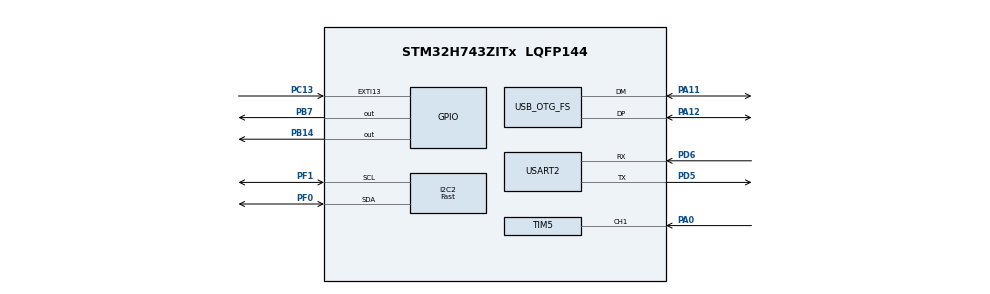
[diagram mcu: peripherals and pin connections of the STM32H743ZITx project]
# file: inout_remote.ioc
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CORTEX_M7.default_mode_Activation=1
Dma.I2C2_TX.0.Direction=DMA_MEMORY_TO_PERIPH
Dma.I2C2_TX.0.EventEnable=DISABLE
Dma.I2C2_TX.0.FIFOMode=DMA_FIFOMODE_DISABLE
Dma.I2C2_TX.0.Instance=DMA1_Stream0
Dma.I2C2_TX.0.MemDataAlignment=DMA_MDATAALIGN_BYTE
Dma.I2C2_TX.0.MemInc=DMA_MINC_ENABLE
Dma.I2C2_TX.0.Mode=DMA_NORMAL
Dma.I2C2_TX.0.PeriphDataAlignment=DMA_PDATAALIGN_BYTE
Dma.I2C2_TX.0.PeriphInc=DMA_PINC_DISABLE
Dma.I2C2_TX.0.Polarity=HAL_DMAMUX_REQ_GEN_RISING
Dma.I2C2_TX.0.Priority=DMA_PRIORITY_HIGH
Dma.I2C2_TX.0.RequestNumber=1
Dma.I2C2_TX.0.SignalID=NONE
Dma.I2C2_TX.0.SyncEnable=DISABLE
Dma.I2C2_TX.0.SyncPolarity=HAL_DMAMUX_SYNC_NO_EVENT
Dma.I2C2_TX.0.SyncRequestNumber=1
Dma.I2C2_TX.0.SyncSignalID=NONE
Dma.Request0=I2C2_TX
I2C2.I2C_Speed_Mode=I2C_Fast
I2C2.Timing=0x00B03FDB
Mcu.Family=STM32H7
Mcu.Name=STM32H743ZITx
Mcu.Package=LQFP144
NUCLEO-H743ZI.BUTTON=1
NUCLEO-H743ZI.Bsp_Common_DEMO=true
NUCLEO-H743ZI.LD1=true
NUCLEO-H743ZI.LD2=true
NUCLEO-H743ZI.LD3=true
NUCLEO-H743ZI.VCP=true
NVIC.DMA1_Stream0_IRQn=true\:0\:0\:false\:false\:true\:false\:true\:true
NVIC.EXTI15_10_IRQn=true\:0\:0\:false\:false\:true\:false\:true\:true
NVIC.OTG_FS_IRQn=true\:0\:0\:false\:false\:true\:false\:true\:true
NVIC.PriorityGroup=NVIC_PRIORITYGROUP_4
NVIC.TIM5_IRQn=true\:0\:0\:false\:false\:true\:true\:true\:true
PA0.Signal=S_TIM5_CH1
PA11.Mode=Device_Only
PA11.Signal=USB_OTG_FS_DM
PA12.Mode=Device_Only
PA12.Signal=USB_OTG_FS_DP
PA13\ (JTMS/SWDIO).GPIO_Label=TMS
PA13\ (JTMS/SWDIO).Signal=DEBUG_JTMS-SWDIO
PA14\ (JTCK/SWCLK).GPIO_Label=TCK
PA14\ (JTCK/SWCLK).Signal=DEBUG_JTCK-SWCLK
PB14.Signal=GPIO_Output
PB3\ (JTDO/TRACESWO).GPIO_Label=SWO
PB3\ (JTDO/TRACESWO).Signal=DEBUG_JTDO-SWO
PB7.Signal=GPIO_Output
PC13.Signal=GPXTI13
PC14-OSC32_IN\ (OSC32_IN).Signal=RCC_OSC32_IN
PC15-OSC32_OUT\ (OSC32_OUT).Signal=RCC_OSC32_OUT
PD5.Mode=Asynchronous
PD5.Signal=USART2_TX
PD6.Mode=Asynchronous
PD6.Signal=USART2_RX
PD8.Signal=USART3_TX
PD9.Signal=USART3_RX
PF0.Mode=I2C
PF0.Signal=I2C2_SDA
PF1.Mode=I2C
PF1.Signal=I2C2_SCL
ProjectManager.HeapSize=0x2000
ProjectManager.StackSize=0x2000
ProjectManager.TargetToolchain=STM32CubeIDE
RCC.48MHZClocksFreq_Value=24000000
RCC.ADCFreq_Value=129000000
RCC.AHBFreq_Value=216000000
RCC.APB1CLKDivider=RCC_HCLK_DIV4
RCC.APB1Freq_Value=120000000
RCC.APB1TimFreq_Value=108000000
RCC.APB2CLKDivider=RCC_HCLK_DIV2
RCC.APB2Freq_Value=120000000
RCC.APB2TimFreq_Value=216000000
RCC.APB3Freq_Value=120000000
RCC.APB4Freq_Value=120000000
RCC.CortexFreq_Value=480000000
RCC.D1PPRE=RCC_APB3_DIV2
RCC.D2PPRE1=RCC_APB1_DIV2
RCC.D2PPRE2=RCC_APB2_DIV2
RCC.D3PPRE=RCC_APB4_DIV2
RCC.DIVM1=4
RCC.DIVN1=60
RCC.DIVQ1=4
RCC.HCLKFreq_Value=240000000
RCC.HPRE=RCC_HCLK_DIV2
RCC.HSE_VALUE=8000000
RCC.HSI_VALUE=64000000
RCC.PLL2FRACN=0
RCC.PLL3FRACN=0
RCC.PLLFRACN=0
RCC.PLLM=25
RCC.PLLMUL=RCC_PLL_MUL9
RCC.PLLN=432
RCC.PLLQ=9
RCC.PRESCALERUSB=RCC_USBCLKSOURCE_PLL_DIV1_5
RCC.PWR_Regulator_Voltage_Scale=PWR_REGULATOR_VOLTAGE_SCALE0
RCC.SYSCLKFreq_VALUE=480000000
RCC.SYSCLKSource=RCC_SYSCLKSOURCE_PLLCLK
RCC.SYSCLKSourceVirtual=RCC_SYSCLKSOURCE_PLLCLK
RCC.USBCLockSelection=RCC_USBCLKSOURCE_HSI48
RCC.USBFreq_Value=48000000
RCC.VCOOutputFreq_Value=432000000
SH.S_TIM5_CH1.0=TIM5_CH1,Input_Capture1_from_TI1
TIM5.AutoReloadPreload=TIM_AUTORELOAD_PRELOAD_DISABLE
TIM5.Channel-Input_Capture1_from_TI1=TIM_CHANNEL_1
TIM5.CounterMode=TIM_COUNTERMODE_UP
TIM5.ICFilter_CH1=10
TIM5.ICPolarity_CH1=TIM_INPUTCHANNELPOLARITY_FALLING
TIM5.Prescaler=239
USART2.VirtualMode-Asynchronous=VM_ASYNC
USB_DEVICE.CLASS_NAME_FS=CDC
USB_DEVICE.VirtualMode-CDC_FS=Cdc
USB_DEVICE.VirtualModeFS=Cdc_FS
USB_OTG_FS.VirtualMode=Device_Only
VP_MEMORYMAP_VS_MEMORYMAP.Mode=CurAppReg
VP_NUCLEO-H743ZI_VS_BSP_COMMON.Mode=COMMON
VP_TIM5_VS_ClockSourceINT.Mode=Internal
VP_USB_DEVICE_VS_USB_DEVICE_CDC_FS.Mode=CDC_FS
board=NUCLEO-H743ZI

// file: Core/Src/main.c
/* USER CODE BEGIN Header */
/**
  ******************************************************************************
  * @file           : main.c
  * @brief          : Main program body
  ******************************************************************************
  * @attention
  *
  * Copyright (c) 2026 STMicroelectronics.
  * All rights reserved.
  *
  * This software is licensed under terms that can be found in the LICENSE file
  * in the root directory of this software component.
  * If no LICENSE file comes with this software, it is provided AS-IS.
  *
  ******************************************************************************
  */
/* USER CODE END Header */
#include "main.h"
#include "dma.h"
#include "i2c.h"
#include "tim.h"
#include "usart.h"
#include "usb_device.h"
#include "gpio.h"

/* USER CODE BEGIN Includes */
#include <stdio.h>
#include "ssd1306.h" // SSD1306 드라이버 헤더 (프로젝트에 있어야 함)
#include "ssd1306_fonts.h"   // 폰트 헤더
#include "usbd_cdc_if.h"
/* USER CODE END Includes */

COM_InitTypeDef BspCOMInit;
__IO uint32_t BspButtonState = BUTTON_RELEASED;

/* USER CODE BEGIN PV */
uint8_t is_work_started = 0;   // 출근 버튼을 누른 적이 있는지 확인하는 플래그
uint32_t lastDisplayUpdate = 0; // 화면 깜빡임 방지용 타이머
/* USER CODE END PV */

void SystemClock_Config(void);
static void MPU_Config(void);
/* USER CODE BEGIN PFP */
void OLED_ShowBitmap_Korean_WorkStart(void);
void OLED_ShowBitmap_Korean_WorkEnd(void);
void OLED_ShowBitmap_Korean_Meeting(void);
void OLED_ShowBitmap_Korean_Trip(void);
void OLED_ShowBitmap_Korean_Away(void);
void OLED_ShowBitmap_Korean_WorkDone(void);
void OLED_ShowUser(int userIndex);
void Display_Countdown(uint32_t remaining_ms);
/* USER CODE END PFP */

/* USER CODE BEGIN 0 */
// 상태 정의
typedef enum {
    STATE_IDLE,
    STATE_WORK_START,   // "출근" 표시 후 5초 대기
    STATE_WORKING,      // 9시간 타이머 작동 중
	STATE_PAUSED,		// 일시정지
    STATE_WORK_DONE,    // "업무시간 종료"
    STATE_MEETING,      // "회의중"
    STATE_TRIP,         // "출장"
    STATE_AWAY          // "부재중"
} SystemState;

SystemState currentState = STATE_IDLE;
int currentUserIndex = 0;
uint32_t stateStartTime = 0;
uint32_t workTimerStart = 0;
const uint32_t WORK_DURATION_MS = 9 * 60 * 60 * 1000; // 9시간

typedef struct {
    SystemState state;          // 현재 상태 (근무중, 회의중 등)
    uint32_t stateStartTime;    // 상태 변경 시각 (5초 문구용)
    uint32_t workTimerStart;    // 업무 시작 시각 (9시간 카운트 기준)
    uint32_t pauseStartTime;    // 일시정지 시작 시각
    uint8_t is_work_started;    // 출근 버튼 눌렀는지 여부 (0 or 1)
} UserData;

UserData users[MAX_USERS];

const unsigned char bitmap_work_start[1024] = {
		0x00, 0x00, 0x00, 0x00, 0x00, 0x00, 0x00, 0x00, 0x00, 0x00, 0x00, 0x00, 0x00, 0x00, 0x00, 0x00,
		0x00, 0x00, 0x00, 0x00, 0x00, 0x00, 0x00, 0x00, 0x00, 0x00, 0x00, 0x00, 0x00, 0x00, 0x00, 0x00,
		0x00, 0x00, 0x00, 0x00, 0x00, 0x00, 0x00, 0x00, 0x00, 0x00, 0x00, 0x00, 0x00, 0x00, 0x00, 0x00,
		0x00, 0x00, 0x00, 0x00, 0x00, 0x00, 0x00, 0x00, 0x00, 0x00, 0x00, 0x00, 0x00, 0x00, 0x00, 0x00,
		0x00, 0x00, 0x00, 0x00, 0x00, 0x00, 0x00, 0x00, 0x00, 0x00, 0x00, 0x00, 0x00, 0x00, 0x00, 0x00,
		0x00, 0x00, 0x00, 0x00, 0x00, 0x00, 0x00, 0x00, 0x00, 0x00, 0x00, 0x00, 0x00, 0x00, 0x00, 0x00,
		0x00, 0x00, 0x00, 0x00, 0x00, 0x00, 0x00, 0x00, 0x00, 0x00, 0x00, 0x00, 0x00, 0x00, 0x00, 0x00,
		0x00, 0x00, 0x00, 0x00, 0x00, 0x00, 0x00, 0x00, 0x00, 0x00, 0x00, 0x00, 0x00, 0x00, 0x00, 0x00,
		0x00, 0x00, 0x00, 0x00, 0x00, 0x00, 0x00, 0x00, 0x00, 0x00, 0x00, 0x00, 0x00, 0x00, 0x00, 0x00,
		0x00, 0x00, 0x00, 0x00, 0x00, 0x00, 0x00, 0x00, 0x00, 0x00, 0x00, 0x00, 0x00, 0x00, 0x00, 0x00,
		0x00, 0x00, 0x00, 0x00, 0x00, 0x00, 0x00, 0x00, 0x00, 0x00, 0x00, 0x00, 0x00, 0x00, 0x00, 0x00,
		0x00, 0x00, 0x00, 0x00, 0x00, 0x00, 0x00, 0x00, 0x00, 0x00, 0x00, 0x00, 0x00, 0x00, 0x00, 0x00,
		0x00, 0x00, 0x00, 0x00, 0x00, 0x00, 0x00, 0x00, 0x00, 0x00, 0x00, 0x00, 0x00, 0x00, 0x00, 0x00,
		0x00, 0x00, 0x00, 0x00, 0x00, 0x00, 0x00, 0x00, 0x00, 0x00, 0x00, 0x00, 0x00, 0x00, 0x00, 0x00,
		0x00, 0x00, 0x00, 0x07, 0x00, 0x00, 0x00, 0x00, 0x00, 0x00, 0x00, 0x00, 0x00, 0x00, 0x00, 0x00,
		0x00, 0x00, 0x00, 0x07, 0x00, 0x00, 0x00, 0x3f, 0xff, 0xff, 0xc0, 0x00, 0x00, 0x00, 0x00, 0x00,
		0x00, 0x00, 0x00, 0x07, 0x00, 0x00, 0x00, 0x3f, 0xff, 0xff, 0xc0, 0x00, 0x00, 0x00, 0x00, 0x00,
		0x00, 0x00, 0x7f, 0xff, 0xff, 0xe0, 0x00, 0x3f, 0xff, 0xff, 0xc0, 0x00, 0x00, 0x00, 0x00, 0x00,
		0x00, 0x00, 0x7f, 0xff, 0xff, 0xe0, 0x00, 0x00, 0x00, 0x01, 0xc0, 0x00, 0x00, 0x00, 0x00, 0x00,
		0x00, 0x00, 0x7f, 0xff, 0xff, 0xe0, 0x00, 0x00, 0x00, 0x01, 0xc0, 0x00, 0x00, 0x00, 0x00, 0x00,
		0x00, 0x00, 0x00, 0x0f, 0x00, 0x00, 0x00, 0x00, 0x00, 0x01, 0xc0, 0x00, 0x00, 0x00, 0x00, 0x00,
		0x00, 0x00, 0x00, 0x1f, 0x80, 0x00, 0x00, 0x00, 0x00, 0x01, 0xc0, 0x00, 0x00, 0x00, 0x00, 0x00,
		0x00, 0x00, 0x00, 0x3f, 0xe0, 0x00, 0x00, 0x00, 0x00, 0x01, 0xc0, 0x00, 0x00, 0x00, 0x00, 0x00,
		0x00, 0x00, 0x00, 0xf8, 0xf8, 0x00, 0x00, 0x00, 0x00, 0x01, 0xc0, 0x00, 0x00, 0x00, 0x00, 0x00,
		0x00, 0x00, 0x0f, 0xe0, 0x7f, 0x80, 0x00, 0x00, 0x00, 0x01, 0xc0, 0x00, 0x00, 0x00, 0x00, 0x00,
		0x00, 0x01, 0xff, 0x80, 0x1f, 0xf8, 0x00, 0x00, 0x00, 0x01, 0xc0, 0x00, 0x00, 0x00, 0x00, 0x00,
		0x00, 0x01, 0xfe, 0x00, 0x03, 0xf8, 0x00, 0x00, 0x00, 0x01, 0xc0, 0x00, 0x00, 0x00, 0x00, 0x00,
		0x00, 0x00, 0xe0, 0x00, 0x00, 0x70, 0x00, 0x00, 0x00, 0x01, 0xc0, 0x00, 0x00, 0x00, 0x00, 0x00,
		0x00, 0x00, 0x00, 0x00, 0x00, 0x00, 0x00, 0x00, 0x00, 0x01, 0xc0, 0x00, 0x00, 0x00, 0x00, 0x00,
		0x00, 0x00, 0x00, 0x00, 0x00, 0x00, 0x00, 0x00, 0x00, 0x01, 0xc0, 0x00, 0x00, 0x00, 0x00, 0x00,
		0x00, 0x07, 0xff, 0xff, 0xff, 0xff, 0x07, 0xff, 0xff, 0xff, 0xff, 0x00, 0x00, 0x00, 0x00, 0x00,
		0x00, 0x07, 0xff, 0xff, 0xff, 0xff, 0x07, 0xff, 0xff, 0xff, 0xff, 0x00, 0x00, 0x00, 0x00, 0x00,
		0x00, 0x07, 0xff, 0xff, 0xff, 0xff, 0x07, 0xff, 0xff, 0xff, 0xff, 0x00, 0x00, 0x00, 0x00, 0x00,
		0x00, 0x00, 0x00, 0x07, 0x00, 0x00, 0x00, 0x00, 0x00, 0x00, 0x00, 0x00, 0x00, 0x00, 0x00, 0x00,
		0x00, 0x00, 0x00, 0x07, 0x00, 0x00, 0x00, 0x00, 0x00, 0x00, 0x00, 0x00, 0x00, 0x00, 0x00, 0x00,
		0x00, 0x00, 0x3f, 0xff, 0xff, 0xc0, 0x00, 0x00, 0x00, 0x00, 0x00, 0x00, 0x00, 0x00, 0x00, 0x00,
		0x00, 0x00, 0x3f, 0xff, 0xff, 0xc0, 0x00, 0x00, 0x00, 0x00, 0x00, 0x00, 0x00, 0x00, 0x00, 0x00,
		0x00, 0x00, 0x3f, 0xff, 0xff, 0xc0, 0x00, 0x1c, 0x00, 0x00, 0x00, 0x00, 0x00, 0x00, 0x00, 0x00,
		0x00, 0x00, 0x00, 0x00, 0x01, 0xc0, 0x00, 0x1c, 0x00, 0x00, 0x00, 0x00, 0x00, 0x00, 0x00, 0x00,
		0x00, 0x00, 0x00, 0x00, 0x01, 0xc0, 0x00, 0x1c, 0x00, 0x00, 0x00, 0x00, 0x00, 0x00, 0x00, 0x00,
		0x00, 0x00, 0x00, 0x00, 0x01, 0xc0, 0x00, 0x1c, 0x00, 0x00, 0x00, 0x00, 0x00, 0x00, 0x00, 0x00,
		0x00, 0x00, 0x3f, 0xff, 0xff, 0xc0, 0x00, 0x1c, 0x00, 0x00, 0x00, 0x00, 0x00, 0x00, 0x00, 0x00,
		0x00, 0x00, 0x3f, 0xff, 0xff, 0xc0, 0x00, 0x1c, 0x00, 0x00, 0x00, 0x00, 0x00, 0x00, 0x00, 0x00,
		0x00, 0x00, 0x3f, 0xff, 0xff, 0xc0, 0x00, 0x1c, 0x00, 0x00, 0x00, 0x00, 0x00, 0x00, 0x00, 0x00,
		0x00, 0x00, 0x38, 0x00, 0x00, 0x00, 0x00, 0x1c, 0x00, 0x00, 0x00, 0x00, 0x00, 0x00, 0x00, 0x00,
		0x00, 0x00, 0x38, 0x00, 0x00, 0x00, 0x00, 0x1c, 0x00, 0x00, 0x00, 0x00, 0x00, 0x00, 0x00, 0x00,
		0x00, 0x00, 0x38, 0x00, 0x00, 0x00, 0x00, 0x1c, 0x00, 0x00, 0x00, 0x00, 0x00, 0x00, 0x00, 0x00,
		0x00, 0x00, 0x3f, 0xff, 0xff, 0xe0, 0x00, 0x1f, 0xff, 0xff, 0xe0, 0x00, 0x00, 0x00, 0x00, 0x00,
		0x00, 0x00, 0x3f, 0xff, 0xff, 0xe0, 0x00, 0x1f, 0xff, 0xff, 0xe0, 0x00, 0x00, 0x00, 0x00, 0x00,
		0x00, 0x00, 0x3f, 0xff, 0xff, 0xe0, 0x00, 0x1f, 0xff, 0xff, 0xe0, 0x00, 0x00, 0x00, 0x00, 0x00,
		0x00, 0x00, 0x00, 0x00, 0x00, 0x00, 0x00, 0x00, 0x00, 0x00, 0x00, 0x00, 0x00, 0x00, 0x00, 0x00,
		0x00, 0x00, 0x00, 0x00, 0x00, 0x00, 0x00, 0x00, 0x00, 0x00, 0x00, 0x00, 0x00, 0x00, 0x00, 0x00,
		0x00, 0x00, 0x00, 0x00, 0x00, 0x00, 0x00, 0x00, 0x00, 0x00, 0x00, 0x00, 0x00, 0x00, 0x00, 0x00,
		0x00, 0x00, 0x00, 0x00, 0x00, 0x00, 0x00, 0x00, 0x00, 0x00, 0x00, 0x00, 0x00, 0x00, 0x00, 0x00,
		0x00, 0x00, 0x00, 0x00, 0x00, 0x00, 0x00, 0x00, 0x00, 0x00, 0x00, 0x00, 0x00, 0x00, 0x00, 0x00,
		0x00, 0x00, 0x00, 0x00, 0x00, 0x00, 0x00, 0x00, 0x00, 0x00, 0x00, 0x00, 0x00, 0x00, 0x00, 0x00,
		0x00, 0x00, 0x00, 0x00, 0x00, 0x00, 0x00, 0x00, 0x00, 0x00, 0x00, 0x00, 0x00, 0x00, 0x00, 0x00,
		0x00, 0x00, 0x00, 0x00, 0x00, 0x00, 0x00, 0x00, 0x00, 0x00, 0x00, 0x00, 0x00, 0x00, 0x00, 0x00,
		0x00, 0x00, 0x00, 0x00, 0x00, 0x00, 0x00, 0x00, 0x00, 0x00, 0x00, 0x00, 0x00, 0x00, 0x00, 0x00,
		0x00, 0x00, 0x00, 0x00, 0x00, 0x00, 0x00, 0x00, 0x00, 0x00, 0x00, 0x00, 0x00, 0x00, 0x00, 0x00,
		0x00, 0x00, 0x00, 0x00, 0x00, 0x00, 0x00, 0x00, 0x00, 0x00, 0x00, 0x00, 0x00, 0x00, 0x00, 0x00,
		0x00, 0x00, 0x00, 0x00, 0x00, 0x00, 0x00, 0x00, 0x00, 0x00, 0x00, 0x00, 0x00, 0x00, 0x00, 0x00,
		0x00, 0x00, 0x00, 0x00, 0x00, 0x00, 0x00, 0x00, 0x00, 0x00, 0x00, 0x00, 0x00, 0x00, 0x00, 0x00,
		0x00, 0x00, 0x00, 0x00, 0x00, 0x00, 0x00, 0x00, 0x00, 0x00, 0x00, 0x00, 0x00, 0x00, 0x00, 0x00
};
const unsigned char bitmap_work_end[1024] = {0x00, 0x00, 0x00, 0x00, 0x00, 0x00, 0x00, 0x00, 0x00, 0x00, 0x00, 0x00, 0x00, 0x00, 0x00, 0x00,
		0x00, 0x00, 0x00, 0x00, 0x00, 0x00, 0x00, 0x00, 0x00, 0x00, 0x00, 0x00, 0x00, 0x00, 0x00, 0x00,
		0x00, 0x00, 0x00, 0x00, 0x00, 0x00, 0x00, 0x00, 0x00, 0x00, 0x00, 0x00, 0x00, 0x00, 0x00, 0x00,
		0x00, 0x00, 0x00, 0x00, 0x00, 0x00, 0x00, 0x00, 0x00, 0x00, 0x00, 0x00, 0x00, 0x00, 0x00, 0x00,
		0x00, 0x00, 0x00, 0x00, 0x00, 0x00, 0x00, 0x00, 0x00, 0x00, 0x00, 0x00, 0x00, 0x00, 0x00, 0x00,
		0x00, 0x00, 0x00, 0x00, 0x00, 0x00, 0x00, 0x00, 0x00, 0x00, 0x00, 0x00, 0x00, 0x00, 0x00, 0x00,
		0x00, 0x00, 0x00, 0x00, 0x00, 0x38, 0x00, 0x00, 0x00, 0x00, 0x00, 0x00, 0x00, 0x00, 0x00, 0x00,
		0x00, 0x00, 0x00, 0x00, 0x00, 0x38, 0x00, 0x1f, 0xff, 0xff, 0xe0, 0x00, 0x00, 0x00, 0x00, 0x00,
		0x00, 0x00, 0x00, 0x00, 0x00, 0x38, 0x00, 0x1f, 0xff, 0xff, 0xe0, 0x00, 0x00, 0x00, 0x00, 0x00,
		0x00, 0x00, 0x00, 0x00, 0x00, 0x38, 0x00, 0x1f, 0xff, 0xff, 0xe0, 0x00, 0x00, 0x00, 0x00, 0x00,
		0x00, 0x00, 0x3f, 0xff, 0xf0, 0x38, 0x00, 0x00, 0x00, 0x00, 0xe0, 0x00, 0x00, 0x00, 0x00, 0x00,
		0x00, 0x00, 0x3f, 0xff, 0xf0, 0x38, 0x00, 0x00, 0x00, 0x00, 0xe0, 0x00, 0x00, 0x00, 0x00, 0x00,
		0x00, 0x00, 0x3f, 0xff, 0xf0, 0x38, 0x00, 0x00, 0x00, 0x00, 0xe0, 0x00, 0x00, 0x00, 0x00, 0x00,
		0x00, 0x00, 0x30, 0x00, 0x00, 0x38, 0x00, 0x00, 0x00, 0x00, 0xe0, 0x00, 0x00, 0x00, 0x00, 0x00,
		0x00, 0x00, 0x30, 0x00, 0x00, 0x38, 0x00, 0x00, 0x00, 0x00, 0xe0, 0x00, 0x00, 0x00, 0x00, 0x00,
		0x00, 0x00, 0x30, 0x00, 0x00, 0x38, 0x00, 0x00, 0x00, 0x00, 0xe0, 0x00, 0x00, 0x00, 0x00, 0x00,
		0x00, 0x00, 0x30, 0x00, 0x00, 0x38, 0x00, 0x00, 0x00, 0x00, 0xe0, 0x00, 0x00, 0x00, 0x00, 0x00,
		0x00, 0x00, 0x3f, 0xff, 0xf0, 0x38, 0x00, 0x00, 0x00, 0x00, 0xe0, 0x00, 0x00, 0x00, 0x00, 0x00,
		0x00, 0x00, 0x3f, 0xff, 0xf0, 0x38, 0x00, 0x00, 0x00, 0x00, 0xe0, 0x00, 0x00, 0x00, 0x00, 0x00,
		0x00, 0x00, 0x3f, 0xff, 0xf0, 0x38, 0x00, 0x00, 0x00, 0x00, 0xe0, 0x00, 0x00, 0x00, 0x00, 0x00,
		0x00, 0x00, 0x30, 0x00, 0x00, 0x38, 0x00, 0x00, 0x00, 0x00, 0xe0, 0x00, 0x00, 0x00, 0x00, 0x00,
		0x00, 0x00, 0x30, 0x00, 0x00, 0x38, 0x00, 0x00, 0x00, 0x00, 0xe0, 0x00, 0x00, 0x00, 0x00, 0x00,
		0x00, 0x00, 0x30, 0x00, 0x00, 0x38, 0x03, 0xff, 0xff, 0xff, 0xff, 0x80, 0x00, 0x00, 0x00, 0x00,
		0x00, 0x00, 0x30, 0x00, 0x00, 0x38, 0x03, 0xff, 0xff, 0xff, 0xff, 0x80, 0x00, 0x00, 0x00, 0x00,
		0x00, 0x00, 0x30, 0x00, 0x00, 0x38, 0x03, 0xff, 0xff, 0xff, 0xff, 0x80, 0x00, 0x00, 0x00, 0x00,
		0x00, 0x00, 0x3f, 0xff, 0xf8, 0x38, 0x00, 0x00, 0x00, 0x00, 0x00, 0x00, 0x00, 0x00, 0x00, 0x00,
		0x00, 0x00, 0x3f, 0xff, 0xf8, 0x38, 0x00, 0x00, 0x00, 0x00, 0x00, 0x00, 0x00, 0x00, 0x00, 0x00,
		0x00, 0x00, 0x3f, 0xff, 0xf8, 0x38, 0x00, 0x00, 0x00, 0x00, 0x00, 0x00, 0x00, 0x00, 0x00, 0x00,
		0x00, 0x00, 0x00, 0x38, 0x00, 0x38, 0x00, 0x00, 0x00, 0x00, 0x00, 0x00, 0x00, 0x00, 0x00, 0x00,
		0x00, 0x00, 0x00, 0x38, 0x00, 0x38, 0x00, 0x0e, 0x00, 0x00, 0x00, 0x00, 0x00, 0x00, 0x00, 0x00,
		0x00, 0x00, 0x00, 0x38, 0x00, 0x38, 0x00, 0x0e, 0x00, 0x00, 0x00, 0x00, 0x00, 0x00, 0x00, 0x00,
		0x00, 0x00, 0x00, 0x38, 0x00, 0x38, 0x00, 0x0e, 0x00, 0x00, 0x00, 0x00, 0x00, 0x00, 0x00, 0x00,
		0x00, 0x00, 0x00, 0x38, 0x00, 0x38, 0x00, 0x0e, 0x00, 0x00, 0x00, 0x00, 0x00, 0x00, 0x00, 0x00,
		0x00, 0x00, 0x00, 0x38, 0x00, 0x38, 0x00, 0x0e, 0x00, 0x00, 0x00, 0x00, 0x00, 0x00, 0x00, 0x00,
		0x00, 0x00, 0x00, 0x38, 0x7f, 0x38, 0x00, 0x0e, 0x00, 0x00, 0x00, 0x00, 0x00, 0x00, 0x00, 0x00,
		0x00, 0x03, 0xff, 0xff, 0xff, 0x38, 0x00, 0x0e, 0x00, 0x00, 0x00, 0x00, 0x00, 0x00, 0x00, 0x00,
		0x00, 0x03, 0xff, 0xff, 0xff, 0x38, 0x00, 0x0e, 0x00, 0x00, 0x00, 0x00, 0x00, 0x00, 0x00, 0x00,
		0x00, 0x03, 0xff, 0xff, 0x80, 0x38, 0x00, 0x0e, 0x00, 0x00, 0x00, 0x00, 0x00, 0x00, 0x00, 0x00,
		0x00, 0x00, 0x00, 0x00, 0x00, 0x38, 0x00, 0x0e, 0x00, 0x00, 0x00, 0x00, 0x00, 0x00, 0x00, 0x00,
		0x00, 0x00, 0x00, 0x00, 0x00, 0x38, 0x00, 0x0f, 0xff, 0xff, 0xf0, 0x00, 0x00, 0x00, 0x00, 0x00,
		0x00, 0x00, 0x00, 0x00, 0x00, 0x38, 0x00, 0x0f, 0xff, 0xff, 0xf0, 0x00, 0x00, 0x00, 0x00, 0x00,
		0x00, 0x00, 0x00, 0x00, 0x00, 0x38, 0x00, 0x0f, 0xff, 0xff, 0xf0, 0x00, 0x00, 0x00, 0x00, 0x00,
		0x00, 0x00, 0x00, 0x00, 0x00, 0x38, 0x00, 0x00, 0x00, 0x00, 0x00, 0x00, 0x00, 0x00, 0x00, 0x00,
		0x00, 0x00, 0x00, 0x00, 0x00, 0x38, 0x00, 0x00, 0x00, 0x00, 0x00, 0x00, 0x00, 0x00, 0x00, 0x00,
		0x00, 0x00, 0x00, 0x00, 0x00, 0x00, 0x00, 0x00, 0x00, 0x00, 0x00, 0x00, 0x00, 0x00, 0x00, 0x00,
		0x00, 0x00, 0x00, 0x00, 0x00, 0x00, 0x00, 0x00, 0x00, 0x00, 0x00, 0x00, 0x00, 0x00, 0x00, 0x00,
		0x00, 0x00, 0x00, 0x00, 0x00, 0x00, 0x00, 0x00, 0x00, 0x00, 0x00, 0x00, 0x00, 0x00, 0x00, 0x00,
		0x00, 0x00, 0x00, 0x00, 0x00, 0x00, 0x00, 0x00, 0x00, 0x00, 0x00, 0x00, 0x00, 0x00, 0x00, 0x00,
		0x00, 0x00, 0x00, 0x00, 0x00, 0x00, 0x00, 0x00, 0x00, 0x00, 0x00, 0x00, 0x00, 0x00, 0x00, 0x00,
		0x00, 0x00, 0x00, 0x00, 0x00, 0x00, 0x00, 0x00, 0x00, 0x00, 0x00, 0x00, 0x00, 0x00, 0x00, 0x00,
		0x00, 0x00, 0x00, 0x00, 0x00, 0x00, 0x00, 0x00, 0x00, 0x00, 0x00, 0x00, 0x00, 0x00, 0x00, 0x00,
		0x00, 0x00, 0x00, 0x00, 0x00, 0x00, 0x00, 0x00, 0x00, 0x00, 0x00, 0x00, 0x00, 0x00, 0x00, 0x00,
		0x00, 0x00, 0x00, 0x00, 0x00, 0x00, 0x00, 0x00, 0x00, 0x00, 0x00, 0x00, 0x00, 0x00, 0x00, 0x00,
		0x00, 0x00, 0x00, 0x00, 0x00, 0x00, 0x00, 0x00, 0x00, 0x00, 0x00, 0x00, 0x00, 0x00, 0x00, 0x00,
		0x00, 0x00, 0x00, 0x00, 0x00, 0x00, 0x00, 0x00, 0x00, 0x00, 0x00, 0x00, 0x00, 0x00, 0x00, 0x00,
		0x00, 0x00, 0x00, 0x00, 0x00, 0x00, 0x00, 0x00, 0x00, 0x00, 0x00, 0x00, 0x00, 0x00, 0x00, 0x00,
		0x00, 0x00, 0x00, 0x00, 0x00, 0x00, 0x00, 0x00, 0x00, 0x00, 0x00, 0x00, 0x00, 0x00, 0x00, 0x00,
		0x00, 0x00, 0x00, 0x00, 0x00, 0x00, 0x00, 0x00, 0x00, 0x00, 0x00, 0x00, 0x00, 0x00, 0x00, 0x00,
		0x00, 0x00, 0x00, 0x00, 0x00, 0x00, 0x00, 0x00, 0x00, 0x00, 0x00, 0x00, 0x00, 0x00, 0x00, 0x00,
		0x00, 0x00, 0x00, 0x00, 0x00, 0x00, 0x00, 0x00, 0x00, 0x00, 0x00, 0x00, 0x00, 0x00, 0x00, 0x00,
		0x00, 0x00, 0x00, 0x00, 0x00, 0x00, 0x00, 0x00, 0x00, 0x00, 0x00, 0x00, 0x00, 0x00, 0x00, 0x00,
		0x00, 0x00, 0x00, 0x00, 0x00, 0x00, 0x00, 0x00, 0x00, 0x00, 0x00, 0x00, 0x00, 0x00, 0x00, 0x00,
		0x00, 0x00, 0x00, 0x00, 0x00, 0x00, 0x00, 0x00, 0x00, 0x00, 0x00, 0x00, 0x00, 0x00, 0x00, 0x00,
		0x00, 0x00, 0x00, 0x00, 0x00, 0x00, 0x00, 0x00, 0x00, 0x00, 0x00, 0x00, 0x00, 0x00, 0x00, 0x00
};   // 퇴근 이미지 데이터
const unsigned char bitmap_meeting[1024] = {0x00, 0x00, 0x00, 0x00, 0x00, 0x00, 0x00, 0x00, 0x00, 0x00, 0x00, 0x00, 0x00, 0x00, 0x00, 0x00,
		0x00, 0x00, 0x00, 0x00, 0x00, 0x00, 0x00, 0x00, 0x00, 0x00, 0x00, 0x00, 0x00, 0x00, 0x00, 0x00,
		0x00, 0x00, 0x00, 0x00, 0x00, 0x00, 0x00, 0x00, 0x00, 0x00, 0x00, 0x00, 0x00, 0x00, 0x00, 0x00,
		0x00, 0x00, 0x00, 0x00, 0x00, 0x00, 0x00, 0x00, 0x00, 0x00, 0x00, 0x00, 0x00, 0x00, 0x00, 0x00,
		0x00, 0x00, 0x03, 0x80, 0x01, 0xc0, 0x00, 0x00, 0x00, 0x01, 0xc0, 0x00, 0x00, 0x00, 0x00, 0x00,
		0x00, 0x00, 0x03, 0x80, 0x01, 0xc0, 0x00, 0x00, 0x00, 0x01, 0xc0, 0x03, 0xff, 0xff, 0xff, 0xc0,
		0x00, 0x00, 0x03, 0x80, 0x01, 0xc0, 0x00, 0x00, 0x00, 0x01, 0xc0, 0x03, 0xff, 0xff, 0xff, 0xc0,
		0x00, 0x00, 0x03, 0x80, 0x01, 0xc0, 0x00, 0x0f, 0xe0, 0x01, 0xc0, 0x03, 0xff, 0xff, 0xff, 0xc0,
		0x00, 0x00, 0x03, 0x80, 0x01, 0xc0, 0x00, 0x3f, 0xf8, 0x01, 0xc0, 0x00, 0x00, 0x3c, 0x00, 0x00,
		0x00, 0x0f, 0xff, 0xff, 0xe1, 0xc0, 0x00, 0xff, 0xfc, 0x01, 0xc0, 0x00, 0x00, 0x7e, 0x00, 0x00,
		0x00, 0x0f, 0xff, 0xff, 0xe1, 0xc0, 0x01, 0xf0, 0x3e, 0x01, 0xc0, 0x00, 0x00, 0xff, 0x00, 0x00,
		0x00, 0x0f, 0xff, 0xff, 0xe1, 0xc0, 0x01, 0xe0, 0x0f, 0x01, 0xc0, 0x00, 0x03, 0xe7, 0xc0, 0x00,
		0x00, 0x00, 0x00, 0x00, 0x01, 0xc0, 0x03, 0xc0, 0x07, 0x81, 0xc0, 0x00, 0x0f, 0xc3, 0xf0, 0x00,
		0x00, 0x00, 0x00, 0x00, 0x01, 0xc0, 0x03, 0x80, 0x03, 0x81, 0xc0, 0x00, 0xff, 0x00, 0xff, 0x00,
		0x00, 0x00, 0x0f, 0xf0, 0x01, 0xc0, 0x03, 0x80, 0x03, 0x81, 0xc0, 0x07, 0xfe, 0x00, 0x3f, 0xf0,
		0x00, 0x00, 0x7f, 0xfc, 0x01, 0xc0, 0x07, 0x00, 0x03, 0x81, 0xc0, 0x07, 0xf0, 0x00, 0x0f, 0xe0,
		0x00, 0x00, 0xff, 0xfe, 0x01, 0xc0, 0x07, 0x00, 0x03, 0x81, 0xc0, 0x03, 0x80, 0x00, 0x01, 0xc0,
		0x00, 0x01, 0xf0, 0x1f, 0x01, 0xc0, 0x03, 0x80, 0x03, 0x81, 0xc0, 0x00, 0x00, 0x00, 0x00, 0x00,
		0x00, 0x01, 0xc0, 0x07, 0x81, 0xc0, 0x03, 0x80, 0x03, 0x81, 0xc0, 0x00, 0x00, 0x00, 0x00, 0x00,
		0x00, 0x03, 0x80, 0x03, 0x81, 0xc0, 0x03, 0xc0, 0x07, 0x81, 0xc0, 0x00, 0x00, 0x00, 0x00, 0x00,
		0x00, 0x03, 0x80, 0x03, 0x81, 0xc0, 0x01, 0xe0, 0x0f, 0x01, 0xc0, 0x1f, 0xff, 0xff, 0xff, 0xfc,
		0x00, 0x03, 0x80, 0x03, 0x81, 0xc0, 0x01, 0xf0, 0x3e, 0x01, 0xc0, 0x1f, 0xff, 0xff, 0xff, 0xfc,
		0x00, 0x03, 0x80, 0x03, 0x81, 0xc0, 0x00, 0xff, 0xfc, 0x01, 0xc0, 0x1f, 0xff, 0xff, 0xff, 0xfc,
		0x00, 0x01, 0xc0, 0x07, 0x81, 0xc0, 0x00, 0x3f, 0xf8, 0x01, 0xc0, 0x00, 0x00, 0x1c, 0x00, 0x00,
		0x00, 0x01, 0xf0, 0x1f, 0x01, 0xc0, 0x00, 0x0f, 0xe0, 0x01, 0xc0, 0x00, 0x00, 0x1c, 0x00, 0x00,
		0x00, 0x00, 0xff, 0xfe, 0x01, 0xc0, 0x00, 0x00, 0x00, 0x01, 0xc0, 0x00, 0x00, 0x1c, 0x00, 0x00,
		0x00, 0x00, 0x7f, 0xfc, 0x01, 0xc0, 0x00, 0x00, 0x00, 0x01, 0xc0, 0x00, 0x00, 0x1c, 0x00, 0x00,
		0x00, 0x00, 0x1f, 0xf0, 0x01, 0xc0, 0x00, 0x00, 0x00, 0x01, 0xc0, 0x00, 0x03, 0xff, 0xc0, 0x00,
		0x00, 0x00, 0x03, 0x80, 0x01, 0xc0, 0x00, 0x00, 0x00, 0x01, 0xc0, 0x00, 0x1f, 0xff, 0xf8, 0x00,
		0x00, 0x00, 0x03, 0x80, 0x01, 0xc0, 0x00, 0x00, 0x00, 0x01, 0xc0, 0x00, 0x3f, 0xff, 0xfc, 0x00,
		0x00, 0x00, 0x03, 0x80, 0x01, 0xc0, 0x00, 0x00, 0x00, 0x01, 0xc0, 0x00, 0x7e, 0x00, 0x3e, 0x00,
		0x00, 0x00, 0x03, 0x80, 0x01, 0xc0, 0x00, 0x00, 0x00, 0x01, 0xc0, 0x00, 0xf0, 0x00, 0x0f, 0x00,
		0x00, 0x00, 0x03, 0x81, 0xf1, 0xc0, 0x00, 0x00, 0x03, 0xf9, 0xc0, 0x00, 0xe0, 0x00, 0x07, 0x00,
		0x00, 0x1f, 0xff, 0xff, 0xf9, 0xc0, 0x1f, 0xff, 0xff, 0xf9, 0xc0, 0x00, 0xe0, 0x00, 0x07, 0x00,
		0x00, 0x1f, 0xff, 0xff, 0xf9, 0xc0, 0x1f, 0xff, 0xff, 0xf9, 0xc0, 0x00, 0xe0, 0x00, 0x07, 0x00,
		0x00, 0x1f, 0xff, 0xfc, 0x01, 0xc0, 0x1f, 0xff, 0xfc, 0x01, 0xc0, 0x00, 0xf0, 0x00, 0x0f, 0x00,
		0x00, 0x00, 0x00, 0x00, 0x01, 0xc0, 0x00, 0x00, 0x00, 0x01, 0xc0, 0x00, 0x7e, 0x00, 0x7e, 0x00,
		0x00, 0x00, 0x00, 0x00, 0x01, 0xc0, 0x00, 0x00, 0x00, 0x01, 0xc0, 0x00, 0x3f, 0xff, 0xfc, 0x00,
		0x00, 0x00, 0x00, 0x00, 0x01, 0xc0, 0x00, 0x00, 0x00, 0x01, 0xc0, 0x00, 0x0f, 0xff, 0xf8, 0x00,
		0x00, 0x00, 0x00, 0x00, 0x01, 0xc0, 0x00, 0x00, 0x00, 0x01, 0xc0, 0x00, 0x01, 0xff, 0xc0, 0x00,
		0x00, 0x00, 0x00, 0x00, 0x01, 0xc0, 0x00, 0x00, 0x00, 0x01, 0xc0, 0x00, 0x00, 0x00, 0x00, 0x00,
		0x00, 0x00, 0x00, 0x00, 0x01, 0xc0, 0x00, 0x00, 0x00, 0x01, 0xc0, 0x00, 0x00, 0x00, 0x00, 0x00,
		0x00, 0x00, 0x00, 0x00, 0x00, 0x00, 0x00, 0x00, 0x00, 0x00, 0x00, 0x00, 0x00, 0x00, 0x00, 0x00,
		0x00, 0x00, 0x00, 0x00, 0x00, 0x00, 0x00, 0x00, 0x00, 0x00, 0x00, 0x00, 0x00, 0x00, 0x00, 0x00,
		0x00, 0x00, 0x00, 0x00, 0x00, 0x00, 0x00, 0x00, 0x00, 0x00, 0x00, 0x00, 0x00, 0x00, 0x00, 0x00,
		0x00, 0x00, 0x00, 0x00, 0x00, 0x00, 0x00, 0x00, 0x00, 0x00, 0x00, 0x00, 0x00, 0x00, 0x00, 0x00,
		0x00, 0x00, 0x00, 0x00, 0x00, 0x00, 0x00, 0x00, 0x00, 0x00, 0x00, 0x00, 0x00, 0x00, 0x00, 0x00,
		0x00, 0x00, 0x00, 0x00, 0x00, 0x00, 0x00, 0x00, 0x00, 0x00, 0x00, 0x00, 0x00, 0x00, 0x00, 0x00,
		0x00, 0x00, 0x00, 0x00, 0x00, 0x00, 0x00, 0x00, 0x00, 0x00, 0x00, 0x00, 0x00, 0x00, 0x00, 0x00,
		0x00, 0x00, 0x00, 0x00, 0x00, 0x00, 0x00, 0x00, 0x00, 0x00, 0x00, 0x00, 0x00, 0x00, 0x00, 0x00,
		0x00, 0x00, 0x00, 0x00, 0x00, 0x00, 0x00, 0x00, 0x00, 0x00, 0x00, 0x00, 0x00, 0x00, 0x00, 0x00,
		0x00, 0x00, 0x00, 0x00, 0x00, 0x00, 0x00, 0x00, 0x00, 0x00, 0x00, 0x00, 0x00, 0x00, 0x00, 0x00,
		0x00, 0x00, 0x00, 0x00, 0x00, 0x00, 0x00, 0x00, 0x00, 0x00, 0x00, 0x00, 0x00, 0x00, 0x00, 0x00,
		0x00, 0x00, 0x00, 0x00, 0x00, 0x00, 0x00, 0x00, 0x00, 0x00, 0x00, 0x00, 0x00, 0x00, 0x00, 0x00,
		0x00, 0x00, 0x00, 0x00, 0x00, 0x00, 0x00, 0x00, 0x00, 0x00, 0x00, 0x00, 0x00, 0x00, 0x00, 0x00,
		0x00, 0x00, 0x00, 0x00, 0x00, 0x00, 0x00, 0x00, 0x00, 0x00, 0x00, 0x00, 0x00, 0x00, 0x00, 0x00,
		0x00, 0x00, 0x00, 0x00, 0x00, 0x00, 0x00, 0x00, 0x00, 0x00, 0x00, 0x00, 0x00, 0x00, 0x00, 0x00,
		0x00, 0x00, 0x00, 0x00, 0x00, 0x00, 0x00, 0x00, 0x00, 0x00, 0x00, 0x00, 0x00, 0x00, 0x00, 0x00,
		0x00, 0x00, 0x00, 0x00, 0x00, 0x00, 0x00, 0x00, 0x00, 0x00, 0x00, 0x00, 0x00, 0x00, 0x00, 0x00,
		0x00, 0x00, 0x00, 0x00, 0x00, 0x00, 0x00, 0x00, 0x00, 0x00, 0x00, 0x00, 0x00, 0x00, 0x00, 0x00,
		0x00, 0x00, 0x00, 0x00, 0x00, 0x00, 0x00, 0x00, 0x00, 0x00, 0x00, 0x00, 0x00, 0x00, 0x00, 0x00,
		0x00, 0x00, 0x00, 0x00, 0x00, 0x00, 0x00, 0x00, 0x00, 0x00, 0x00, 0x00, 0x00, 0x00, 0x00, 0x00,
		0x00, 0x00, 0x00, 0x00, 0x00, 0x00, 0x00, 0x00, 0x00, 0x00, 0x00, 0x00, 0x00, 0x00, 0x00, 0x00,
		0x00, 0x00, 0x00, 0x00, 0x00, 0x00, 0x00, 0x00, 0x00, 0x00, 0x00, 0x00, 0x00, 0x00, 0x00, 0x00
};    // 회의중 이미지 데이터
const unsigned char bitmap_trip[1024] = {0x00, 0x00, 0x00, 0x00, 0x00, 0x00, 0x00, 0x00, 0x00, 0x00, 0x00, 0x00, 0x00, 0x00, 0x00, 0x00,
		0x00, 0x00, 0x00, 0x00, 0x00, 0x00, 0x00, 0x00, 0x00, 0x00, 0x00, 0x00, 0x00, 0x00, 0x00, 0x00,
		0x00, 0x00, 0x00, 0x00, 0x00, 0x00, 0x00, 0x00, 0x00, 0x00, 0x00, 0x00, 0x00, 0x00, 0x00, 0x00,
		0x00, 0x00, 0x00, 0x00, 0x00, 0x00, 0x00, 0x00, 0x00, 0x00, 0x00, 0x00, 0x00, 0x00, 0x00, 0x00,
		0x00, 0x00, 0x1c, 0x00, 0x00, 0x00, 0x00, 0x00, 0x07, 0x00, 0x00, 0x00, 0x00, 0x00, 0x00, 0x00,
		0x00, 0x00, 0x1c, 0x00, 0x00, 0x00, 0x00, 0x00, 0x07, 0x00, 0x03, 0xff, 0xff, 0xff, 0xc0, 0x00,
		0x00, 0x00, 0x1c, 0x00, 0x00, 0x0f, 0xff, 0xfe, 0x07, 0x00, 0x03, 0xff, 0xff, 0xff, 0xc0, 0x00,
		0x01, 0xff, 0xff, 0xff, 0x80, 0x0f, 0xff, 0xfe, 0x07, 0x00, 0x03, 0xff, 0xff, 0xff, 0xc0, 0x00,
		0x01, 0xff, 0xff, 0xff, 0x80, 0x0f, 0xff, 0xfe, 0x07, 0x00, 0x00, 0x00, 0x3c, 0x00, 0x00, 0x00,
		0x01, 0xff, 0xff, 0xff, 0x80, 0x00, 0x0e, 0x00, 0x07, 0x00, 0x00, 0x00, 0x7e, 0x00, 0x00, 0x00,
		0x00, 0x00, 0x3c, 0x00, 0x00, 0x00, 0x0e, 0x00, 0x07, 0x00, 0x00, 0x00, 0xff, 0x00, 0x00, 0x00,
		0x00, 0x00, 0x7e, 0x00, 0x00, 0x00, 0x0e, 0x00, 0x07, 0x00, 0x00, 0x03, 0xe7, 0xc0, 0x00, 0x00,
		0x00, 0x00, 0xff, 0x80, 0x00, 0x00, 0x0f, 0x00, 0x07, 0x00, 0x00, 0x0f, 0xc3, 0xf0, 0x00, 0x00,
		0x00, 0x03, 0xe3, 0xe0, 0x00, 0x00, 0x1f, 0x00, 0x07, 0x00, 0x00, 0xff, 0x00, 0xff, 0x00, 0x00,
		0x00, 0x3f, 0x81, 0xfe, 0x00, 0x00, 0x1f, 0x80, 0x07, 0xfc, 0x07, 0xfe, 0x00, 0x3f, 0xf0, 0x00,
		0x07, 0xfe, 0x00, 0x7f, 0xe0, 0x00, 0x3f, 0x80, 0x07, 0xfc, 0x07, 0xf0, 0x00, 0x0f, 0xe0, 0x00,
		0x07, 0xf8, 0x00, 0x0f, 0xe0, 0x00, 0x79, 0xc0, 0x07, 0xfc, 0x03, 0x80, 0x00, 0x01, 0xc0, 0x00,
		0x03, 0x80, 0x00, 0x01, 0xc0, 0x00, 0xf1, 0xe0, 0x07, 0x00, 0x00, 0x00, 0x00, 0x00, 0x00, 0x00,
		0x00, 0x00, 0x00, 0x00, 0x00, 0x01, 0xf0, 0xf8, 0x07, 0x00, 0x00, 0x00, 0x00, 0x00, 0x00, 0x00,
		0x00, 0x00, 0x00, 0x00, 0x00, 0x03, 0xe0, 0x3e, 0x07, 0x00, 0x00, 0x00, 0x00, 0x00, 0x00, 0x00,
		0x1f, 0xff, 0xff, 0xff, 0xfc, 0x0f, 0xc0, 0x1f, 0x07, 0x00, 0x1f, 0xff, 0xff, 0xff, 0xfc, 0x00,
		0x1f, 0xff, 0xff, 0xff, 0xfc, 0x1f, 0x00, 0x0f, 0x07, 0x00, 0x1f, 0xff, 0xff, 0xff, 0xfc, 0x00,
		0x1f, 0xff, 0xff, 0xff, 0xfc, 0x0e, 0x00, 0x02, 0x07, 0x00, 0x1f, 0xff, 0xff, 0xff, 0xfc, 0x00,
		0x00, 0x00, 0x1c, 0x00, 0x00, 0x0c, 0x00, 0x00, 0x07, 0x00, 0x00, 0x00, 0x1c, 0x00, 0x00, 0x00,
		0x00, 0x00, 0x1c, 0x00, 0x00, 0x00, 0x00, 0x00, 0x07, 0x00, 0x00, 0x00, 0x1c, 0x00, 0x00, 0x00,
		0x00, 0xff, 0xff, 0xff, 0x00, 0x00, 0x00, 0x00, 0x00, 0x00, 0x00, 0x00, 0x1c, 0x00, 0x00, 0x00,
		0x00, 0xff, 0xff, 0xff, 0x00, 0x00, 0x01, 0xff, 0xc0, 0x00, 0x00, 0x00, 0x1c, 0x00, 0x00, 0x00,
		0x00, 0xff, 0xff, 0xff, 0x00, 0x00, 0x0f, 0xff, 0xf8, 0x00, 0x00, 0x03, 0xff, 0xc0, 0x00, 0x00,
		0x00, 0x00, 0x00, 0x07, 0x00, 0x00, 0x1f, 0xff, 0xfc, 0x00, 0x00, 0x1f, 0xff, 0xf8, 0x00, 0x00,
		0x00, 0x00, 0x00, 0x07, 0x00, 0x00, 0x3e, 0x00, 0x7e, 0x00, 0x00, 0x3f, 0xff, 0xfc, 0x00, 0x00,
		0x00, 0x00, 0x00, 0x07, 0x00, 0x00, 0x78, 0x00, 0x0f, 0x00, 0x00, 0x7e, 0x00, 0x3e, 0x00, 0x00,
		0x00, 0xff, 0xff, 0xff, 0x00, 0x00, 0xf0, 0x00, 0x07, 0x00, 0x00, 0xf0, 0x00, 0x0f, 0x00, 0x00,
		0x00, 0xff, 0xff, 0xff, 0x00, 0x00, 0xe0, 0x00, 0x03, 0x80, 0x00, 0xe0, 0x00, 0x07, 0x00, 0x00,
		0x00, 0xff, 0xff, 0xff, 0x00, 0x00, 0xe0, 0x00, 0x03, 0x80, 0x00, 0xe0, 0x00, 0x07, 0x00, 0x00,
		0x00, 0xe0, 0x00, 0x00, 0x00, 0x00, 0xf0, 0x00, 0x07, 0x00, 0x00, 0xe0, 0x00, 0x07, 0x00, 0x00,
		0x00, 0xe0, 0x00, 0x00, 0x00, 0x00, 0x78, 0x00, 0x0f, 0x00, 0x00, 0xf0, 0x00, 0x0f, 0x00, 0x00,
		0x00, 0xe0, 0x00, 0x00, 0x00, 0x00, 0x3f, 0x00, 0x7e, 0x00, 0x00, 0x7e, 0x00, 0x7e, 0x00, 0x00,
		0x00, 0xff, 0xff, 0xff, 0x80, 0x00, 0x1f, 0xff, 0xfc, 0x00, 0x00, 0x3f, 0xff, 0xfc, 0x00, 0x00,
		0x00, 0xff, 0xff, 0xff, 0x80, 0x00, 0x0f, 0xff, 0xf8, 0x00, 0x00, 0x0f, 0xff, 0xf8, 0x00, 0x00,
		0x00, 0xff, 0xff, 0xff, 0x80, 0x00, 0x01, 0xff, 0xc0, 0x00, 0x00, 0x01, 0xff, 0xc0, 0x00, 0x00,
		0x00, 0x00, 0x00, 0x00, 0x00, 0x00, 0x00, 0x00, 0x00, 0x00, 0x00, 0x00, 0x00, 0x00, 0x00, 0x00,
		0x00, 0x00, 0x00, 0x00, 0x00, 0x00, 0x00, 0x00, 0x00, 0x00, 0x00, 0x00, 0x00, 0x00, 0x00, 0x00,
		0x00, 0x00, 0x00, 0x00, 0x00, 0x00, 0x00, 0x00, 0x00, 0x00, 0x00, 0x00, 0x00, 0x00, 0x00, 0x00,
		0x00, 0x00, 0x00, 0x00, 0x00, 0x00, 0x00, 0x00, 0x00, 0x00, 0x00, 0x00, 0x00, 0x00, 0x00, 0x00,
		0x00, 0x00, 0x00, 0x00, 0x00, 0x00, 0x00, 0x00, 0x00, 0x00, 0x00, 0x00, 0x00, 0x00, 0x00, 0x00,
		0x00, 0x00, 0x00, 0x00, 0x00, 0x00, 0x00, 0x00, 0x00, 0x00, 0x00, 0x00, 0x00, 0x00, 0x00, 0x00,
		0x00, 0x00, 0x00, 0x00, 0x00, 0x00, 0x00, 0x00, 0x00, 0x00, 0x00, 0x00, 0x00, 0x00, 0x00, 0x00,
		0x00, 0x00, 0x00, 0x00, 0x00, 0x00, 0x00, 0x00, 0x00, 0x00, 0x00, 0x00, 0x00, 0x00, 0x00, 0x00,
		0x00, 0x00, 0x00, 0x00, 0x00, 0x00, 0x00, 0x00, 0x00, 0x00, 0x00, 0x00, 0x00, 0x00, 0x00, 0x00,
		0x00, 0x00, 0x00, 0x00, 0x00, 0x00, 0x00, 0x00, 0x00, 0x00, 0x00, 0x00, 0x00, 0x00, 0x00, 0x00,
		0x00, 0x00, 0x00, 0x00, 0x00, 0x00, 0x00, 0x00, 0x00, 0x00, 0x00, 0x00, 0x00, 0x00, 0x00, 0x00,
		0x00, 0x00, 0x00, 0x00, 0x00, 0x00, 0x00, 0x00, 0x00, 0x00, 0x00, 0x00, 0x00, 0x00, 0x00, 0x00,
		0x00, 0x00, 0x00, 0x00, 0x00, 0x00, 0x00, 0x00, 0x00, 0x00, 0x00, 0x00, 0x00, 0x00, 0x00, 0x00,
		0x00, 0x00, 0x00, 0x00, 0x00, 0x00, 0x00, 0x00, 0x00, 0x00, 0x00, 0x00, 0x00, 0x00, 0x00, 0x00,
		0x00, 0x00, 0x00, 0x00, 0x00, 0x00, 0x00, 0x00, 0x00, 0x00, 0x00, 0x00, 0x00, 0x00, 0x00, 0x00,
		0x00, 0x00, 0x00, 0x00, 0x00, 0x00, 0x00, 0x00, 0x00, 0x00, 0x00, 0x00, 0x00, 0x00, 0x00, 0x00,
		0x00, 0x00, 0x00, 0x00, 0x00, 0x00, 0x00, 0x00, 0x00, 0x00, 0x00, 0x00, 0x00, 0x00, 0x00, 0x00,
		0x00, 0x00, 0x00, 0x00, 0x00, 0x00, 0x00, 0x00, 0x00, 0x00, 0x00, 0x00, 0x00, 0x00, 0x00, 0x00,
		0x00, 0x00, 0x00, 0x00, 0x00, 0x00, 0x00, 0x00, 0x00, 0x00, 0x00, 0x00, 0x00, 0x00, 0x00, 0x00,
		0x00, 0x00, 0x00, 0x00, 0x00, 0x00, 0x00, 0x00, 0x00, 0x00, 0x00, 0x00, 0x00, 0x00, 0x00, 0x00,
		0x00, 0x00, 0x00, 0x00, 0x00, 0x00, 0x00, 0x00, 0x00, 0x00, 0x00, 0x00, 0x00, 0x00, 0x00, 0x00,
		0x00, 0x00, 0x00, 0x00, 0x00, 0x00, 0x00, 0x00, 0x00, 0x00, 0x00, 0x00, 0x00, 0x00, 0x00, 0x00,
		0x00, 0x00, 0x00, 0x00, 0x00, 0x00, 0x00, 0x00, 0x00, 0x00, 0x00, 0x00, 0x00, 0x00, 0x00, 0x00,
		0x00, 0x00, 0x00, 0x00, 0x00, 0x00, 0x00, 0x00, 0x00, 0x00, 0x00, 0x00, 0x00, 0x00, 0x00, 0x00};       // 출장 이미지 데이터
const unsigned char bitmap_away[1024] = {0x00, 0x00, 0x00, 0x00, 0x00, 0x00, 0x00, 0x00, 0x00, 0x00, 0x00, 0x00, 0x00, 0x00, 0x00, 0x00,
		0x00, 0x00, 0x00, 0x00, 0x00, 0x00, 0x00, 0x00, 0x00, 0x00, 0x00, 0x00, 0x00, 0x00, 0x00, 0x00,
		0x00, 0x00, 0x00, 0x00, 0x00, 0x00, 0x00, 0x00, 0x00, 0x00, 0x00, 0x00, 0x00, 0x00, 0x00, 0x00,
		0x00, 0x00, 0x00, 0x00, 0x00, 0x00, 0x00, 0x00, 0x00, 0x00, 0x00, 0x00, 0x00, 0x00, 0x00, 0x00,
		0x00, 0x00, 0x00, 0x00, 0x00, 0x00, 0x00, 0x00, 0x00, 0x00, 0x00, 0x00, 0x00, 0x00, 0x00, 0x00,
		0x00, 0x00, 0x00, 0x00, 0x00, 0x00, 0x00, 0x00, 0x00, 0xe0, 0x00, 0x00, 0x00, 0x00, 0x00, 0x00,
		0x00, 0xe0, 0x00, 0x07, 0x00, 0x00, 0x00, 0x00, 0xe0, 0xe0, 0x03, 0xff, 0xff, 0xff, 0xc0, 0x00,
		0x00, 0xe0, 0x00, 0x07, 0x00, 0x00, 0x00, 0x00, 0xe0, 0xe0, 0x03, 0xff, 0xff, 0xff, 0xc0, 0x00,
		0x00, 0xe0, 0x00, 0x07, 0x00, 0x0f, 0xff, 0xfc, 0xe0, 0xe0, 0x03, 0xff, 0xff, 0xff, 0xc0, 0x00,
		0x00, 0xe0, 0x00, 0x07, 0x00, 0x0f, 0xff, 0xfc, 0xe0, 0xe0, 0x00, 0x00, 0x3c, 0x00, 0x00, 0x00,
		0x00, 0xe0, 0x00, 0x07, 0x00, 0x0f, 0xff, 0xfc, 0xe0, 0xe0, 0x00, 0x00, 0x7e, 0x00, 0x00, 0x00,
		0x00, 0xff, 0xff, 0xff, 0x00, 0x00, 0x0c, 0x00, 0xe0, 0xe0, 0x00, 0x00, 0xff, 0x00, 0x00, 0x00,
		0x00, 0xff, 0xff, 0xff, 0x00, 0x00, 0x0c, 0x00, 0xe0, 0xe0, 0x00, 0x03, 0xe7, 0xc0, 0x00, 0x00,
		0x00, 0xff, 0xff, 0xff, 0x00, 0x00, 0x0c, 0x00, 0xe0, 0xe0, 0x00, 0x0f, 0xc3, 0xf0, 0x00, 0x00,
		0x00, 0xe0, 0x00, 0x07, 0x00, 0x00, 0x0c, 0x00, 0xe0, 0xe0, 0x00, 0xff, 0x00, 0xff, 0x00, 0x00,
		0x00, 0xe0, 0x00, 0x07, 0x00, 0x00, 0x0c, 0x00, 0xe0, 0xe0, 0x07, 0xfe, 0x00, 0x3f, 0xf0, 0x00,
		0x00, 0xe0, 0x00, 0x07, 0x00, 0x00, 0x0c, 0x00, 0xe0, 0xe0, 0x07, 0xf0, 0x00, 0x0f, 0xe0, 0x00,
		0x00, 0xe0, 0x00, 0x07, 0x00, 0x00, 0x1c, 0x00, 0xe0, 0xe0, 0x03, 0x80, 0x00, 0x01, 0xc0, 0x00,
		0x00, 0xe0, 0x00, 0x07, 0x00, 0x00, 0x1e, 0x00, 0xe0, 0xe0, 0x00, 0x00, 0x00, 0x00, 0x00, 0x00,
		0x00, 0xff, 0xff, 0xff, 0x00, 0x00, 0x1e, 0x00, 0xe0, 0xe0, 0x00, 0x00, 0x00, 0x00, 0x00, 0x00,
		0x00, 0xff, 0xff, 0xff, 0x00, 0x00, 0x1e, 0x00, 0xe0, 0xe0, 0x00, 0x00, 0x00, 0x00, 0x00, 0x00,
		0x00, 0xff, 0xff, 0xff, 0x00, 0x00, 0x1e, 0x00, 0xe0, 0xe0, 0x1f, 0xff, 0xff, 0xff, 0xfc, 0x00,
		0x00, 0x00, 0x00, 0x00, 0x00, 0x00, 0x3e, 0x00, 0xff, 0xe0, 0x1f, 0xff, 0xff, 0xff, 0xfc, 0x00,
		0x00, 0x00, 0x00, 0x00, 0x00, 0x00, 0x3f, 0x00, 0xff, 0xe0, 0x1f, 0xff, 0xff, 0xff, 0xfc, 0x00,
		0x00, 0x00, 0x00, 0x00, 0x00, 0x00, 0x77, 0x00, 0xff, 0xe0, 0x00, 0x00, 0x1c, 0x00, 0x00, 0x00,
		0x00, 0x00, 0x00, 0x00, 0x00, 0x00, 0x73, 0x80, 0xe0, 0xe0, 0x00, 0x00, 0x1c, 0x00, 0x00, 0x00,
		0x00, 0x00, 0x00, 0x00, 0x00, 0x00, 0xe3, 0x80, 0xe0, 0xe0, 0x00, 0x00, 0x1c, 0x00, 0x00, 0x00,
		0x1f, 0xff, 0xff, 0xff, 0xfc, 0x00, 0xe1, 0xc0, 0xe0, 0xe0, 0x00, 0x00, 0x1c, 0x00, 0x00, 0x00,
		0x1f, 0xff, 0xff, 0xff, 0xfc, 0x01, 0xc0, 0xe0, 0xe0, 0xe0, 0x00, 0x03, 0xff, 0xc0, 0x00, 0x00,
		0x1f, 0xff, 0xff, 0xff, 0xfc, 0x03, 0x80, 0xe0, 0xe0, 0xe0, 0x00, 0x1f, 0xff, 0xf8, 0x00, 0x00,
		0x00, 0x00, 0x1c, 0x00, 0x00, 0x07, 0x80, 0x70, 0xe0, 0xe0, 0x00, 0x3f, 0xff, 0xfc, 0x00, 0x00,
		0x00, 0x00, 0x1c, 0x00, 0x00, 0x0f, 0x00, 0x38, 0xe0, 0xe0, 0x00, 0x7e, 0x00, 0x3e, 0x00, 0x00,
		0x00, 0x00, 0x1c, 0x00, 0x00, 0x1e, 0x00, 0x1c, 0xe0, 0xe0, 0x00, 0xf0, 0x00, 0x0f, 0x00, 0x00,
		0x00, 0x00, 0x1c, 0x00, 0x00, 0x04, 0x00, 0x08, 0xe0, 0xe0, 0x00, 0xe0, 0x00, 0x07, 0x00, 0x00,
		0x00, 0x00, 0x1c, 0x00, 0x00, 0x00, 0x00, 0x00, 0xe0, 0xe0, 0x00, 0xe0, 0x00, 0x07, 0x00, 0x00,
		0x00, 0x00, 0x1c, 0x00, 0x00, 0x00, 0x00, 0x00, 0xe0, 0xe0, 0x00, 0xe0, 0x00, 0x07, 0x00, 0x00,
		0x00, 0x00, 0x1c, 0x00, 0x00, 0x00, 0x00, 0x00, 0xe0, 0xe0, 0x00, 0xf0, 0x00, 0x0f, 0x00, 0x00,
		0x00, 0x00, 0x1c, 0x00, 0x00, 0x00, 0x00, 0x00, 0xe0, 0xe0, 0x00, 0x7e, 0x00, 0x7e, 0x00, 0x00,
		0x00, 0x00, 0x1c, 0x00, 0x00, 0x00, 0x00, 0x00, 0xe0, 0xe0, 0x00, 0x3f, 0xff, 0xfc, 0x00, 0x00,
		0x00, 0x00, 0x1c, 0x00, 0x00, 0x00, 0x00, 0x00, 0xe0, 0xe0, 0x00, 0x0f, 0xff, 0xf8, 0x00, 0x00,
		0x00, 0x00, 0x1c, 0x00, 0x00, 0x00, 0x00, 0x00, 0xe0, 0xe0, 0x00, 0x01, 0xff, 0xc0, 0x00, 0x00,
		0x00, 0x00, 0x1c, 0x00, 0x00, 0x00, 0x00, 0x00, 0xe0, 0xe0, 0x00, 0x00, 0x00, 0x00, 0x00, 0x00,
		0x00, 0x00, 0x1c, 0x00, 0x00, 0x00, 0x00, 0x00, 0x00, 0xe0, 0x00, 0x00, 0x00, 0x00, 0x00, 0x00,
		0x00, 0x00, 0x00, 0x00, 0x00, 0x00, 0x00, 0x00, 0x00, 0x00, 0x00, 0x00, 0x00, 0x00, 0x00, 0x00,
		0x00, 0x00, 0x00, 0x00, 0x00, 0x00, 0x00, 0x00, 0x00, 0x00, 0x00, 0x00, 0x00, 0x00, 0x00, 0x00,
		0x00, 0x00, 0x00, 0x00, 0x00, 0x00, 0x00, 0x00, 0x00, 0x00, 0x00, 0x00, 0x00, 0x00, 0x00, 0x00,
		0x00, 0x00, 0x00, 0x00, 0x00, 0x00, 0x00, 0x00, 0x00, 0x00, 0x00, 0x00, 0x00, 0x00, 0x00, 0x00,
		0x00, 0x00, 0x00, 0x00, 0x00, 0x00, 0x00, 0x00, 0x00, 0x00, 0x00, 0x00, 0x00, 0x00, 0x00, 0x00,
		0x00, 0x00, 0x00, 0x00, 0x00, 0x00, 0x00, 0x00, 0x00, 0x00, 0x00, 0x00, 0x00, 0x00, 0x00, 0x00,
		0x00, 0x00, 0x00, 0x00, 0x00, 0x00, 0x00, 0x00, 0x00, 0x00, 0x00, 0x00, 0x00, 0x00, 0x00, 0x00,
		0x00, 0x00, 0x00, 0x00, 0x00, 0x00, 0x00, 0x00, 0x00, 0x00, 0x00, 0x00, 0x00, 0x00, 0x00, 0x00,
		0x00, 0x00, 0x00, 0x00, 0x00, 0x00, 0x00, 0x00, 0x00, 0x00, 0x00, 0x00, 0x00, 0x00, 0x00, 0x00,
		0x00, 0x00, 0x00, 0x00, 0x00, 0x00, 0x00, 0x00, 0x00, 0x00, 0x00, 0x00, 0x00, 0x00, 0x00, 0x00,
		0x00, 0x00, 0x00, 0x00, 0x00, 0x00, 0x00, 0x00, 0x00, 0x00, 0x00, 0x00, 0x00, 0x00, 0x00, 0x00,
		0x00, 0x00, 0x00, 0x00, 0x00, 0x00, 0x00, 0x00, 0x00, 0x00, 0x00, 0x00, 0x00, 0x00, 0x00, 0x00,
		0x00, 0x00, 0x00, 0x00, 0x00, 0x00, 0x00, 0x00, 0x00, 0x00, 0x00, 0x00, 0x00, 0x00, 0x00, 0x00,
		0x00, 0x00, 0x00, 0x00, 0x00, 0x00, 0x00, 0x00, 0x00, 0x00, 0x00, 0x00, 0x00, 0x00, 0x00, 0x00,
		0x00, 0x00, 0x00, 0x00, 0x00, 0x00, 0x00, 0x00, 0x00, 0x00, 0x00, 0x00, 0x00, 0x00, 0x00, 0x00,
		0x00, 0x00, 0x00, 0x00, 0x00, 0x00, 0x00, 0x00, 0x00, 0x00, 0x00, 0x00, 0x00, 0x00, 0x00, 0x00,
		0x00, 0x00, 0x00, 0x00, 0x00, 0x00, 0x00, 0x00, 0x00, 0x00, 0x00, 0x00, 0x00, 0x00, 0x00, 0x00,
		0x00, 0x00, 0x00, 0x00, 0x00, 0x00, 0x00, 0x00, 0x00, 0x00, 0x00, 0x00, 0x00, 0x00, 0x00, 0x00,
		0x00, 0x00, 0x00, 0x00, 0x00, 0x00, 0x00, 0x00, 0x00, 0x00, 0x00, 0x00, 0x00, 0x00, 0x00, 0x00,
		0x00, 0x00, 0x00, 0x00, 0x00, 0x00, 0x00, 0x00, 0x00, 0x00, 0x00, 0x00, 0x00, 0x00, 0x00, 0x00,
		0x00, 0x00, 0x00, 0x00, 0x00, 0x00, 0x00, 0x00, 0x00, 0x00, 0x00, 0x00, 0x00, 0x00, 0x00, 0x00};       // 부재중 이미지 데이터
const unsigned char bitmap_work_done[1024] = {0, };  // 업무종료 이미지 데이터

// --- IR 수신 관련 변수 (전역 변수로 선언하거나 상단에 두세요) ---
uint32_t ir_last_capture = 0;   // 이전 캡처 시간
uint32_t ir_received_code = 0;  // 현재 조립 중인 코드
int ir_bit_count = 0;           // 비트 수 카운트 (0~32)
uint8_t ir_data_ready = 0;      // [플래그] 데이터 완성됨! (main loop에서 확인용)
uint32_t final_ir_code = 0;     // [결과] 최종 완성된 리모컨 코드
uint32_t pauseStartTime = 0;	// 일시정지 시작 시간 기록용 변수
/* USER CODE END 0 */

int main(void)
{

  /* USER CODE BEGIN 1 */
  //SCB_DisableDCache();
  /* USER CODE END 1 */

  /* MPU Configuration--------------------------------------------------------*/
  MPU_Config();

  /* MCU Configuration--------------------------------------------------------*/

  /* Reset of all peripherals, Initializes the Flash interface and the Systick. */
  HAL_Init();

  /* Configure the system clock */
  SystemClock_Config();

  /* Initialize all configured peripherals */
  MX_GPIO_Init();
  MX_DMA_Init();
  MX_TIM5_Init();
  MX_USB_DEVICE_Init();
  MX_I2C2_Init();
  MX_USART2_UART_Init();
  /* USER CODE BEGIN 2 */
  // 1. OLED 초기화
  ssd1306_Init();
  HAL_TIM_IC_Start_IT(&htim5, TIM_CHANNEL_1);
  /* USER CODE END 2 */

  /* Initialize leds */
  BSP_LED_Init(LED_GREEN);
  BSP_LED_Init(LED_BLUE);
  BSP_LED_Init(LED_RED);

  /* Initialize USER push-button, will be used to trigger an interrupt each time it's pressed.*/
  BSP_PB_Init(BUTTON_USER, BUTTON_MODE_EXTI);

  /* Initialize COM1 port (115200, 8 bits (7-bit data + 1 stop bit), no parity */
  BspCOMInit.BaudRate   = 115200;
  BspCOMInit.WordLength = COM_WORDLENGTH_8B;
  BspCOMInit.StopBits   = COM_STOPBITS_1;
  BspCOMInit.Parity     = COM_PARITY_NONE;
  BspCOMInit.HwFlowCtl  = COM_HWCONTROL_NONE;
  if (BSP_COM_Init(COM1, &BspCOMInit) != BSP_ERROR_NONE)
  {
    Error_Handler();
  }

  /* USER CODE BEGIN BSP */

  /* -- Sample board code to send message over COM1 port ---- */
  printf("Welcome to STM32 world !\n\r");

  /* -- Sample board code to switch on leds ---- */
  BSP_LED_On(LED_BLUE);

  /* USER CODE END BSP */

  /* Infinite loop */
  /* USER CODE BEGIN WHILE */
  // 모든 유저의 데이터를 0(IDLE)으로 초기화
    for(int i=0; i < MAX_USERS; i++) {
        users[i].state = STATE_IDLE;
        users[i].stateStartTime = 0;
        users[i].workTimerStart = 0;
        users[i].pauseStartTime = 0;
        users[i].is_work_started = 0;
    }
    OLED_ShowUser(currentUserIndex);
  while (1)
  {
    /* USER CODE END WHILE */

    /* USER CODE BEGIN 3 */
   // 1. IR 리모컨 입력 처리
   if (ir_data_ready) {
	   ir_data_ready = 0;

	   UserData *pUser = &users[currentUserIndex];

       switch (final_ir_code) {
           case IR_KEY_1: // 출근
               pUser->state = STATE_WORK_START;
               pUser->stateStartTime = HAL_GetTick();
               OLED_ShowBitmap_Korean_WorkStart(); // "출근" 비트맵 출력
               // PC로 전송: CMD:START:유저인덱스
               printf("CMD:START:%d\r\n", currentUserIndex);
               //출근 플래그
               pUser->is_work_started = 1;
               break;

           case IR_KEY_2: // 퇴근
        	   pUser->state = STATE_IDLE; // 퇴근 후 대기 상태로
               OLED_ShowBitmap_Korean_WorkEnd(); // "퇴근" 비트맵 출력
               printf("CMD:END:%d\r\n", currentUserIndex);
               // 퇴근했으면 타이머 복귀 불가
               pUser->is_work_started = 0;
               break;

           case IR_KEY_3: // 회의중
        	   pUser->state = STATE_MEETING;
               OLED_ShowBitmap_Korean_Meeting();
               break;

           case IR_KEY_4: // 출장
        	   pUser->state = STATE_TRIP;
               OLED_ShowBitmap_Korean_Trip();
               break;

           case IR_KEY_5: // 부재중
        	   pUser->state = STATE_AWAY;
               OLED_ShowBitmap_Korean_Away();
               break;

           case IR_KEY_6: // 복귀 (Resume)
               if (pUser->is_work_started == 1) {
                   if (pUser->state == STATE_PAUSED) {
                       uint32_t pauseDuration = HAL_GetTick() - pUser->pauseStartTime;
                       pUser->workTimerStart += pauseDuration; // 쉰 만큼 시작 시간 미룸
                   }
                   pUser->state = STATE_WORKING;
                   lastDisplayUpdate = 0; // 즉시 갱신
               }
               break;

           case IR_KEY_7: // 일시정지 (Pause)
               if (pUser->is_work_started == 1 && pUser->state != STATE_PAUSED) {
                   pUser->state = STATE_PAUSED;
                   pUser->pauseStartTime = HAL_GetTick();
                   OLED_ShowBitmap_Korean_Away();
               }
               break;

           case IR_KEY_UP: // 다음 유저
               currentUserIndex = (currentUserIndex + 1) % MAX_USERS;
               lastDisplayUpdate = 0; // 화면 즉시 갱신
               // ★ 유저 변경 시 화면 강제 업데이트 로직 (아래 참고)
               break;

           case IR_KEY_DOWN: // 이전 유저
               if (currentUserIndex == 0) currentUserIndex = MAX_USERS - 1;
               else currentUserIndex--;
               lastDisplayUpdate = 0;
               break;
		}
   }

   // 2. 시간 기반 상태 관리 (현재 선택된 유저 기준)
   UserData *curr = &users[currentUserIndex]; // 현재 유저 별칭

   if (curr->state == STATE_WORK_START) {
       if (HAL_GetTick() - curr->stateStartTime >= 5000) {
           curr->state = STATE_WORKING;
           curr->workTimerStart = HAL_GetTick();
           lastDisplayUpdate = 0;
       }
   }
   else if (curr->state == STATE_WORKING) {
       uint32_t currentTick = HAL_GetTick();
       uint32_t elapsed = currentTick - curr->workTimerStart;

       if (elapsed >= 9 * 60 * 60 * 1000) {
           curr->state = STATE_WORK_DONE;
           OLED_ShowBitmap_Korean_WorkDone();
       } else {
           if (currentTick - lastDisplayUpdate >= 1000) {
               lastDisplayUpdate = currentTick;
               Display_Countdown(9 * 60 * 60 * 1000 - elapsed);
           }
       }
   }
   // ★ 중요: 유저를 바꿨을 때 그 유저의 상태를 바로 보여주는 로직
   else if (curr->state == STATE_IDLE && lastDisplayUpdate == 0) {
       OLED_ShowUser(currentUserIndex); // 대기 중이면 유저 번호 표시
       lastDisplayUpdate = HAL_GetTick(); // 계속 그리지 않게 막음
   }
   else if (curr->state == STATE_PAUSED && lastDisplayUpdate == 0) {
       OLED_ShowBitmap_Korean_Away(); // 일시정지 화면 복구
       lastDisplayUpdate = HAL_GetTick();
   }
//           case IR_KEY_6: // 타이머 화면으로 복귀
//        	   if (is_work_started == 1)
//        	   {
//        	       // 일시정지 상태였다면, 쉬었던 시간만큼 시작 시간을 뒤로 미룸
//        	       if (pUser->state == STATE_PAUSED)
//        	       {
//        	           uint32_t currentTick = HAL_GetTick();
//
//        	           // (현재시간 - 아까 멈춘 시간) = 쉰 시간
//        	           uint32_t pauseDuration = currentTick - pauseStartTime;
//
//        	           // 시작 시간을 쉰 만큼 더해줌 (Start Time이 미래로 밀림 -> 경과 시간은 줄어듦)
//        	           workTimerStart += pauseDuration;
//
//        	           printf("Resumed! Paused for: %lu ms\r\n", pauseDuration);
//        	       }
//
//        	       // 상태를 다시 '근무중'으로 변경
//        	       pUser->state = STATE_WORKING;
//
//        	       // 즉시 화면 갱신을 위해 타이머 리셋 (매우 중요)
//        	       lastDisplayUpdate = 0;
//        	   }
//        	   break;
//           case IR_KEY_7: // 타이머 화면으로 복귀
//        	   if (is_work_started == 1 && pUser->state != STATE_PAUSED) // 근무 중일 때만 정지 가능
//        	   {
//        		   pUser->state = STATE_PAUSED;
//
//        	       // 1. 언제 멈췄는지 기록
//        	       pauseStartTime = HAL_GetTick();
//
//        	       // 2. 화면에 "자리비움" 또는 "일시정지" 표시
//        	       OLED_ShowBitmap_Korean_Away(); // 기존에 만든 부재중 비트맵 재활용
//        	       // 또는 ssd1306_WriteString("PAUSED", Font_11x18, White); 사용
//
//        	   }
//        	   break;
//
//           case IR_KEY_UP: // 유저 변경 (다음)
//               currentUserIndex = (currentUserIndex + 1) % MAX_USERS;
//               OLED_ShowUser(currentUserIndex); // "USER 1", "USER 2" 등으로 표시
//               break;
//
//           case IR_KEY_DOWN: // 유저 변경 (이전)
//               if (currentUserIndex == 0) currentUserIndex = MAX_USERS - 1;
//               else currentUserIndex--;
//               OLED_ShowUser(currentUserIndex);
//               break;
//
//           default:
//        	   printf("%d", final_ir_code);
//       }
//       ir_data_ready = 0; // 플래그 초기화
//   }
//
//   // 2. 시간 기반 상태 관리 (타이머 로직)
//   if (pUser->state == STATE_WORK_START) {
//       // 3초가 지났는지 확인
//       if (HAL_GetTick() - stateStartTime >= 3000) {
//    	   pUser->state = STATE_WORKING;
//           workTimerStart = HAL_GetTick(); // 카운트다운 시작 시간 기록
//       }
//   } else if (pUser->state == STATE_WORKING) {
//	   uint32_t currentTick = HAL_GetTick(); // 현재 시간 가져오기
//       uint32_t elapsed = HAL_GetTick() - workTimerStart;
//       if (elapsed >= WORK_DURATION_MS) {
//    	   pUser->state = STATE_WORK_DONE;
//           OLED_ShowBitmap_Korean_WorkDone(); // "업무시간 종료"
//       } else {
//    	   lastDisplayUpdate = currentTick;
//           // 남은 시간 계산 및 OLED 표시 (1초마다 갱신)
//           uint32_t remaining = WORK_DURATION_MS - elapsed;
//           Display_Countdown(remaining);
//       }
//   }
//  }
  }
  /* USER CODE END 3 */
}

void SystemClock_Config(void)
{
  RCC_OscInitTypeDef RCC_OscInitStruct = {0};
  RCC_ClkInitTypeDef RCC_ClkInitStruct = {0};

  /** Supply configuration update enable
  */
  HAL_PWREx_ConfigSupply(PWR_LDO_SUPPLY);

  /** Configure the main internal regulator output voltage
  */
  __HAL_PWR_VOLTAGESCALING_CONFIG(PWR_REGULATOR_VOLTAGE_SCALE0);

  while(!__HAL_PWR_GET_FLAG(PWR_FLAG_VOSRDY)) {}

  /** Initializes the RCC Oscillators according to the specified parameters
  * in the RCC_OscInitTypeDef structure.
  */
  RCC_OscInitStruct.OscillatorType = RCC_OSCILLATORTYPE_HSI48|RCC_OSCILLATORTYPE_HSI;
  RCC_OscInitStruct.HSIState = RCC_HSI_DIV1;
  RCC_OscInitStruct.HSICalibrationValue = RCC_HSICALIBRATION_DEFAULT;
  RCC_OscInitStruct.HSI48State = RCC_HSI48_ON;
  RCC_OscInitStruct.PLL.PLLState = RCC_PLL_ON;
  RCC_OscInitStruct.PLL.PLLSource = RCC_PLLSOURCE_HSI;
  RCC_OscInitStruct.PLL.PLLM = 4;
  RCC_OscInitStruct.PLL.PLLN = 60;
  RCC_OscInitStruct.PLL.PLLP = 2;
  RCC_OscInitStruct.PLL.PLLQ = 4;
  RCC_OscInitStruct.PLL.PLLR = 2;
  RCC_OscInitStruct.PLL.PLLRGE = RCC_PLL1VCIRANGE_3;
  RCC_OscInitStruct.PLL.PLLVCOSEL = RCC_PLL1VCOWIDE;
  RCC_OscInitStruct.PLL.PLLFRACN = 0;
  if (HAL_RCC_OscConfig(&RCC_OscInitStruct) != HAL_OK)
  {
    Error_Handler();
  }

  /** Initializes the CPU, AHB and APB buses clocks
  */
  RCC_ClkInitStruct.ClockType = RCC_CLOCKTYPE_HCLK|RCC_CLOCKTYPE_SYSCLK
                              |RCC_CLOCKTYPE_PCLK1|RCC_CLOCKTYPE_PCLK2
                              |RCC_CLOCKTYPE_D3PCLK1|RCC_CLOCKTYPE_D1PCLK1;
  RCC_ClkInitStruct.SYSCLKSource = RCC_SYSCLKSOURCE_PLLCLK;
  RCC_ClkInitStruct.SYSCLKDivider = RCC_SYSCLK_DIV1;
  RCC_ClkInitStruct.AHBCLKDivider = RCC_HCLK_DIV2;
  RCC_ClkInitStruct.APB3CLKDivider = RCC_APB3_DIV2;
  RCC_ClkInitStruct.APB1CLKDivider = RCC_APB1_DIV2;
  RCC_ClkInitStruct.APB2CLKDivider = RCC_APB2_DIV2;
  RCC_ClkInitStruct.APB4CLKDivider = RCC_APB4_DIV2;

  if (HAL_RCC_ClockConfig(&RCC_ClkInitStruct, FLASH_LATENCY_4) != HAL_OK)
  {
    Error_Handler();
  }
}

/* USER CODE BEGIN 4 */
// 1. 출근 화면
void OLED_ShowBitmap_Korean_WorkStart(void) {
    ssd1306_Fill(Black); // 화면 지우기
    // 0,0 좌표에 128x64 크기로 비트맵 출력 (흰색)
    ssd1306_DrawBitmap(0, 0, bitmap_work_start, 128, 64, White);
    ssd1306_UpdateScreen(); // 화면 갱신
}

// 2. 퇴근 화면
void OLED_ShowBitmap_Korean_WorkEnd(void) {
    ssd1306_Fill(Black);
    ssd1306_DrawBitmap(0, 0, bitmap_work_end, 128, 64, White);
    ssd1306_UpdateScreen();
}

// 3. 회의중 화면
void OLED_ShowBitmap_Korean_Meeting(void) {
    ssd1306_Fill(Black);
    ssd1306_DrawBitmap(0, 0, bitmap_meeting, 128, 64, White);
    ssd1306_UpdateScreen();
}

// 4. 출장 화면
void OLED_ShowBitmap_Korean_Trip(void) {
    ssd1306_Fill(Black);
    ssd1306_DrawBitmap(0, 0, bitmap_trip, 128, 64, White);
    ssd1306_UpdateScreen();
}

// 5. 부재중 화면
void OLED_ShowBitmap_Korean_Away(void) {
    ssd1306_Fill(Black);
    ssd1306_DrawBitmap(0, 0, bitmap_away, 128, 64, White);
    ssd1306_UpdateScreen();
}

// 6. 업무 종료 화면
void OLED_ShowBitmap_Korean_WorkDone(void) {
    ssd1306_Fill(Black);
    ssd1306_DrawBitmap(0, 0, bitmap_work_done, 128, 64, White);
    ssd1306_UpdateScreen();
}

// 7. 사용자 정보 표시 함수
void OLED_ShowUser(int userIndex) {
    char strBuffer[20];

    ssd1306_Fill(Black);

    // 상단 제목
    ssd1306_SetCursor(10, 10);
    ssd1306_WriteString("SELECT USER", Font_7x10, White); // 폰트 크기는 라이브러리에 따라 다름

    // 사용자 번호 출력
    snprintf(strBuffer, sizeof(strBuffer), "USER: %d", userIndex + 1); // 0번 인덱스를 1번으로 표시
    ssd1306_SetCursor(20, 30);
    ssd1306_WriteString(strBuffer, Font_11x18, White);

    ssd1306_UpdateScreen();
}

// 8. 카운트다운 타이머 표시 함수
void Display_Countdown(uint32_t remaining_ms) {
    char timeStr[20];

    // 밀리초를 시:분:초로 변환
    uint32_t total_seconds = remaining_ms / 1000;
    uint32_t hours = total_seconds / 3600;
    uint32_t minutes = (total_seconds % 3600) / 60;
    uint32_t seconds = total_seconds % 60;

    ssd1306_Fill(Black);

    // 상태 메시지 (영어로 대체, 비트맵 쓰기엔 숫자가 계속 바뀌므로)
    ssd1306_SetCursor(25, 10);
    ssd1306_WriteString("WORKING...", Font_7x10, White);

    // 시간 출력 (예: 08:59:59)
    snprintf(timeStr, sizeof(timeStr), "%02lu:%02lu:%02lu", hours, minutes, seconds);
    ssd1306_SetCursor(15, 30);
    ssd1306_WriteString(timeStr, Font_11x18, White);

    ssd1306_UpdateScreen();
}

void HAL_TIM_IC_CaptureCallback(TIM_HandleTypeDef *htim)
{
	  BSP_LED_On(LED_RED);
    // 우리가 설정한 TIM5 채널 1인지 확인
    if (htim->Instance == TIM5 && htim->Channel == HAL_TIM_ACTIVE_CHANNEL_1)
    {
        // 1. 현재 타이머 값 읽기 (1us 단위)
        uint32_t current_capture = HAL_TIM_ReadCapturedValue(htim, TIM_CHANNEL_1);

        // 2. 시간 차이 계산 (Up Counter이므로 현재 - 과거)
        // 32비트 오버플로우는 자동 계산되므로 신경 안 써도 됨
        uint32_t diff = current_capture - ir_last_capture;
        ir_last_capture = current_capture;

        // 3. NEC 프로토콜 분석 (오차 범위 ±20% 정도 감안)

        // A. Leader Code (Start 신호): 약 13.5ms (13500us)
        // 범위: 12000 ~ 15000
        if (diff > 12000 && diff < 15000)
        {
            ir_received_code = 0;
            ir_bit_count = 0;
        }
        // B. Data '1': 약 2.25ms (2250us)
        // 범위: 2000 ~ 2500
        else if (diff > 2000 && diff < 2500)
        {
            // 1비트 추가 (Shift 후 1 더하기)
            ir_received_code = (ir_received_code << 1) | 1;
            ir_bit_count++;
        }
        // C. Data '0': 약 1.12ms (1120us)
        // 범위: 900 ~ 1300
        else if (diff > 900 && diff < 1300)
        {
            // 0비트 추가 (Shift만 함)
            ir_received_code = (ir_received_code << 1);
            ir_bit_count++;
        }
        // D. Repeat Code (꾹 누르고 있을 때): 약 11.25ms
        // 필요하면 구현 (지금은 무시)

        // 4. 32비트가 모두 모였는지 확인
        if (ir_bit_count == 32)
        {
            final_ir_code = ir_received_code;
            ir_data_ready = 1; // 메인 루프에게 "코드 왔어!"라고 알림
            ir_bit_count = 0;  // 초기화
        }
    }

    BSP_LED_Off(LED_RED);
}

int _write(int file, char *ptr, int len)
{
  // USB 전송 (CDC_Transmit_FS 함수 사용)
  // 연결이 안 되어 있거나 바쁘면 전송이 실패할 수 있으므로 상태 체크
  uint8_t result = CDC_Transmit_FS((uint8_t*)ptr, len);

  return len;
}

/* USER CODE END 4 */

 /* MPU Configuration */

void MPU_Config(void)
{
  MPU_Region_InitTypeDef MPU_InitStruct = {0};

  /* Disables the MPU */
  HAL_MPU_Disable();

  /** Initializes and configures the Region and the memory to be protected
  */
  MPU_InitStruct.Enable = MPU_REGION_ENABLE;
  MPU_InitStruct.Number = MPU_REGION_NUMBER0;
  MPU_InitStruct.BaseAddress = 0x0;
  MPU_InitStruct.Size = MPU_REGION_SIZE_4GB;
  MPU_InitStruct.SubRegionDisable = 0x87;
  MPU_InitStruct.TypeExtField = MPU_TEX_LEVEL0;
  MPU_InitStruct.AccessPermission = MPU_REGION_NO_ACCESS;
  MPU_InitStruct.DisableExec = MPU_INSTRUCTION_ACCESS_DISABLE;
  MPU_InitStruct.IsShareable = MPU_ACCESS_SHAREABLE;
  MPU_InitStruct.IsCacheable = MPU_ACCESS_NOT_CACHEABLE;
  MPU_InitStruct.IsBufferable = MPU_ACCESS_NOT_BUFFERABLE;

  HAL_MPU_ConfigRegion(&MPU_InitStruct);
  /* Enables the MPU */
  HAL_MPU_Enable(MPU_PRIVILEGED_DEFAULT);

}

/**
  * @brief BSP Push Button callback
  * @param Button Specifies the pressed button
  * @retval None
  */
void BSP_PB_Callback(Button_TypeDef Button)
{
  if (Button == BUTTON_USER)
  {
    BspButtonState = BUTTON_PRESSED;
  }
}

void Error_Handler(void)
{
  __disable_irq();
  while (1)
  {
  }
}
